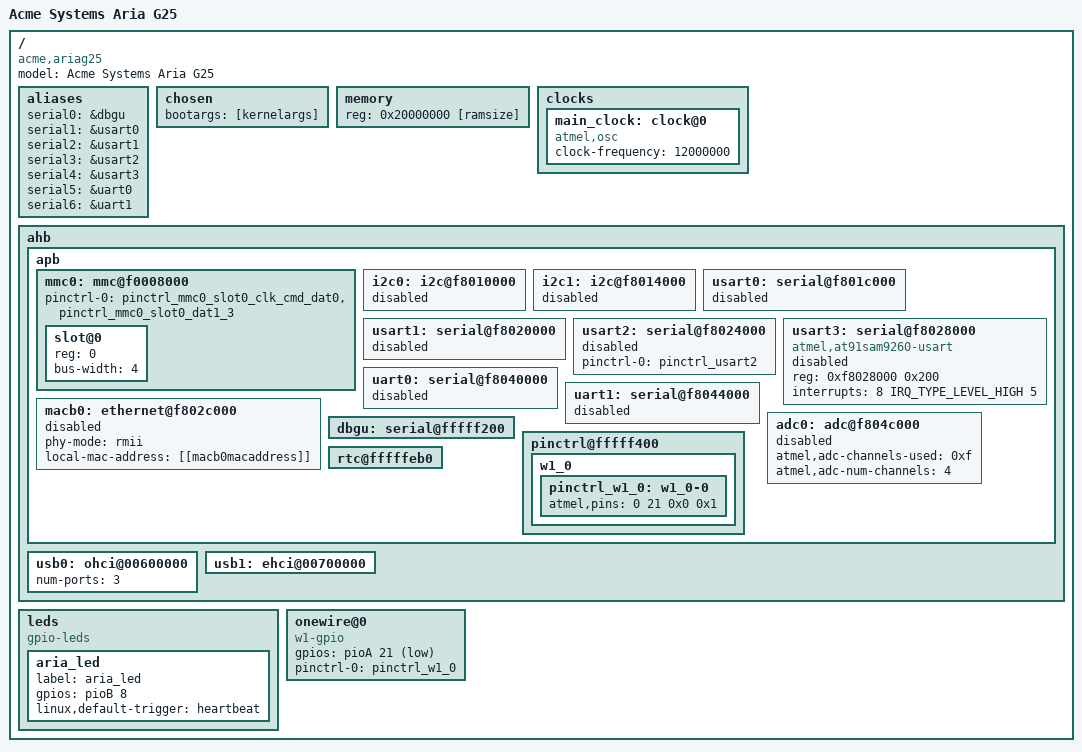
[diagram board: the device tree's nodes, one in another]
/*
 * at91-ariag25.dts - Device Tree file for Acme Systems Aria G25
 *
 * Copyright (C) 2013 Douglas Gilbert <dgilbert@interlog.com>,
 *                    Robert Nelson <robertcnelson@gmail.com>
 *
 * [copyright]
 *
 * Licensed under GPLv2 or later.
 */
/dts-v1/;
#include "at91sam9g25.dtsi"

/ {
	model = "Acme Systems Aria G25";
	compatible = "acme,ariag25", "atmel,at91sam9x5ek",
		     "atmel,at91sam9x5", "atmel,at91sam9";

	aliases {
		serial0 = &dbgu;
		serial1 = &usart0;
		serial2 = &usart1;
		serial3 = &usart2;
		serial4 = &usart3;
		serial5 = &uart0;
		serial6 = &uart1;
	};

	chosen {
		bootargs = "[kernelargs]";
	};

	memory {
		reg = <0x20000000 [ramsize]>;
	};

	clocks {
		#address-cells = <1>;
		#size-cells = <1>;
		ranges;

		main_clock: clock@0 {
			compatible = "atmel,osc", "fixed-clock";
			clock-frequency = <12000000>;
		};
	};

	ahb {
		apb {
			mmc0: mmc@f0008000 {
				pinctrl-0 = <
					&pinctrl_mmc0_slot0_clk_cmd_dat0
					&pinctrl_mmc0_slot0_dat1_3>;
				status = "okay";
				slot@0 {
					reg = <0>;
					bus-width = <4>;
				};
			};

			i2c0: i2c@f8010000 {
				status = "[i2c0status]";
			};

			i2c1: i2c@f8014000 {
				status = "[i2c1status]";
			};

			/* /dev/ttyS1 */
			usart0: serial@f801c000 {
				[usart0pinctrl]
				[usart0rs485atboottime]
				[usart0rs485rtsdelay]
				status = "[usart0status]";
			};

			/* /dev/ttyS2 */
			usart1: serial@f8020000 {
				[usart1pinctrl]
				[usart1rs485atboottime]
				[usart1rs485rtsdelay]
				status = "[usart1status]";
			};

			/* /dev/ttyS3 */
			usart2: serial@f8024000 {
				pinctrl-0 = <&pinctrl_usart2>;
				status = "[usart2status]";
			};

			/* /dev/ttyS4 */
			usart3: serial@f8028000 {
				compatible = "atmel,at91sam9260-usart";
				reg = <0xf8028000 0x200>;
				interrupts = <8 IRQ_TYPE_LEVEL_HIGH 5>;
				pinctrl-names = "default";
			
				[usart3pinctrl]
				[usart3rs485atboottime]
				[usart3rs485rtsdelay]
				 status = "[usart3status]";
			};

			/* /dev/ttyS5 */
			uart0: serial@f8040000 {
				status = "[uart0status]";
			};

			/* /dev/ttyS6 */
			uart1: serial@f8044000 {
				status = "[uart1status]";
			};

			macb0: ethernet@f802c000 {
				phy-mode = "rmii";
				local-mac-address = [[macb0macaddress]];
				status = "[macb0status]";
			};

			adc0: adc@f804c000 {
				status = "[adcstatus]";
				atmel,adc-channels-used = <0xf>;
				atmel,adc-num-channels = <4>;
			};

			dbgu: serial@fffff200 {
				status = "okay";
			};

			pinctrl@fffff400 {
				w1_0 {
					pinctrl_w1_0: w1_0-0 {
						atmel,pins = <0 21 0x0 0x1>; /* PA21 PIO, pull-up */
					};
				};
			};

			rtc@fffffeb0 {
				status = "okay";
			};
		};

		usb0: ohci@00600000 {
			status = "okay";
			num-ports = <3>;
		};

		usb1: ehci@00700000 {
			status = "okay";
		};
	};

	leds {
		compatible = "gpio-leds";

		aria_led {
			label = "aria_led";
			gpios = <&pioB 8 GPIO_ACTIVE_HIGH>; /* PB8 */
			linux,default-trigger = "heartbeat";
		};

	};

	onewire@0 {
		compatible = "w1-gpio";
		gpios = <&pioA 21 GPIO_ACTIVE_LOW>;
		pinctrl-names = "default";
		pinctrl-0 = <&pinctrl_w1_0>;
	};
};
